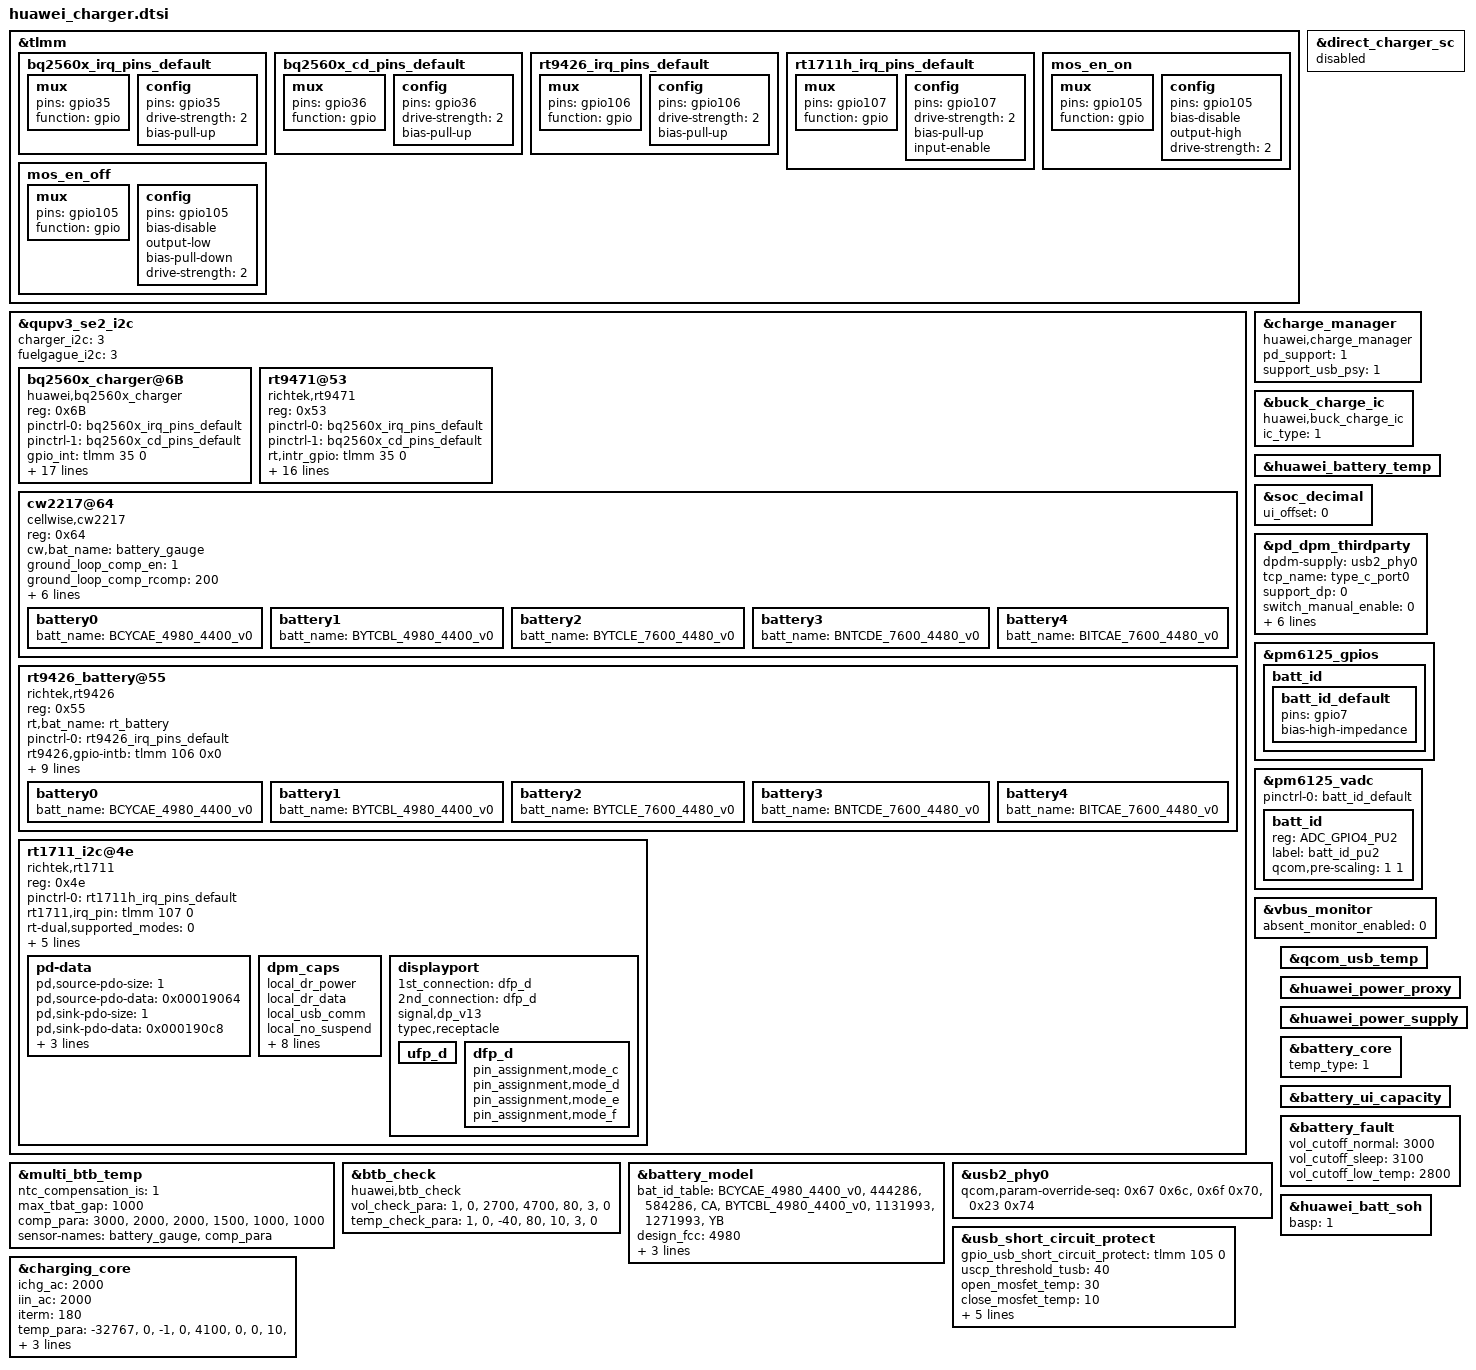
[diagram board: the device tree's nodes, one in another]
&tlmm {
	bq2560x_irq_pins_default: bq2560x_irq_pins_default {
		mux {
			pins = "gpio35";
			function = "gpio";
		};
		config {
			pins = "gpio35";
			drive-strength = <2>;
			bias-pull-up;
		};
	};

	bq2560x_cd_pins_default: bq2560x_cd_pins_default {
		mux {
			pins = "gpio36";
			function = "gpio";
		};
		config {
			pins = "gpio36";
			drive-strength = <2>;
			bias-pull-up;
		};
	};

	rt9426_irq_pins_default: rt9426_irq_pins_default {
		mux {
			pins = "gpio106";
			function = "gpio";
		};
		config {
			pins = "gpio106";
			drive-strength = <2>;
			bias-pull-up;
		};
	};

	rt1711h_irq_pins_default: rt1711h_irq_pins_default {
		mux {
			pins = "gpio107";
			function = "gpio";
		};
		config {
			pins = "gpio107";
			drive-strength = <2>;
			bias-pull-up;
			input-enable;
		};
	};

	mos_en_on: mos_en_on {
		mux {
			pins = "gpio105";
			function = "gpio";
		};

		config {
			pins = "gpio105";
			bias-disable;
			output-high;
			drive-strength = <2>; /* 2 MA */
		};
	};

	mos_en_off: mos_en_off {
		mux {
			pins = "gpio105";
			function = "gpio";
		};

		config {
			pins = "gpio105";
			bias-disable;
			output-low;
			bias-pull-down; /* PULL DOWN */
			drive-strength = <2>; /* 2 MA */
		};
	};
};

&direct_charger_sc {
	status = "disable";
};

&qupv3_se2_i2c {
	status = "ok";

	/* auto_key_info @ name: charger_i2c type: uint32 default: 0 */
	charger_i2c = <3>;
	/* auto_key_info @ name: fuelgague_i2c type: uint32 default: 0 */
	fuelgague_i2c = <3>;

	bq2560x_charger@6B{
		compatible = "huawei,bq2560x_charger";
		reg = <0x6B>;
		pinctrl-names = "bq2560x_irq_pins_default",
						"bq2560x_cd_pins_default";
		pinctrl-0 = <&bq2560x_irq_pins_default>;
		pinctrl-1 = <&bq2560x_cd_pins_default>;
		gpio_int = <&tlmm 35 0>;
		gpio_cd = <&tlmm 36 0>;
		bat_comp = <80>;
		vclamp = <224>;
		rilim = <124>;
		adc_channel_iin = <5>;
		adc_channel_vbat_sys = <14>;
		fcp_support = <0>;
		hiz_iin_limit = <1>;
		custom_cv = <4464>;
		chg_en_vac_ovp = <1>; /* vac_ovp:6.5v */
		dischg_vac_ovp = <1>; /* vac_ovp:6.5v */
		iprechg_cur = <120>; /* mA */
		otg_boost_vol = <2>; /* boost voltage:5.15v */
		ieoc = <180>; /* mA */
		charge-detect-enable;
		enable_redo_bc12;
		no_need_change_iterm;
		status = "ok";
	};

	rt9471@53 {
		compatible = "richtek,rt9471";
		reg = <0x53>;
		pinctrl-names = "bq2560x_irq_pins_default",
						"bq2560x_cd_pins_default";
		pinctrl-0 = <&bq2560x_irq_pins_default>;
		pinctrl-1 = <&bq2560x_cd_pins_default>;
		rt,intr_gpio = <&tlmm 35 0>;
		rt,ceb_gpio = <&tlmm 36 0>;
		charger_name = "rt9471";
		interrupt-names = "wdt", "vac_ov", "otg_fault";
		ichg = <1000>; /* mA */
		aicr = <500>; /* mA */
		acov = <6500>; /* mV */
		mivr = <4500>; /* mV */
		cv = <4400>; /* mV */
		custom_cv = <4464>;
		ieoc = <150>; /* mA */
		safe-tmr = <20>; /* hour */
		wdt = <40>; /* sec */
		mivr-track = <0>;
		en-te;
		/* en-jeita; */
		/* ceb-invert; */
		/* dis-i2c-tout; */
		en-qon-rst;
		/* auto-aicr; */
		charge-detect-enable;
		enable_redo_bc12;
		status = "ok";
	};

	cw2217@64 {
		compatible = "cellwise,cw2217";
		reg = <0x64>;
		cw,bat_name = "battery_gauge";
		status = "ok";
		ground_loop_comp_en = <1>;
		ground_loop_comp_rcomp = <200>;
		en_soft_reset = <1>;
		vbat_soc_table =
			"3783", "3781", "30",
			"3800", "3797", "36",
			"3825", "3821", "43",
			"3854", "3847", "49",
			"3892", "3882", "55",
			"3952", "3947", "62",
			"4004", "3996", "68",
			"4065", "4064", "74",
			"4136", "4132", "81",
			"4198", "4196", "87",
			"4274", "4274", "94",
			"4355", "4356", "100";
		battery0{
			batt_name = "BCYCAE_4980_4400_v0";
			#include "../../../huawei_charger/cw2217_BCYCAE_4980mAh_4V4_BT062.dtsi"
		};
		battery1{
			batt_name = "BYTCBL_4980_4400_v0";
			#include "../../../huawei_charger/cw2217_BYTCBL_4980mAh_4V4_BT062.dtsi"
		};
		battery2{
			batt_name = "BYTCLE_7600_4480_v0";
			#include "../../../huawei_charger/cw2217_BYTCLE_7600mAh_4V48_BT274.dtsi"
		};
		battery3{
			batt_name = "BNTCDE_7600_4480_v0";
			#include "../../../huawei_charger/cw2217_BNTCDE_7600mAh_4V48_BT274.dtsi"
		};
		battery4{
			batt_name = "BITCAE_7600_4480_v0";
			#include "../../../huawei_charger/cw2217_BITCAE_7600mAh_4V48_BT274.dtsi"
		};
	};

	rt9426_battery@55{
		reg = <0x55>;
		rt,bat_name = "rt_battery";
		compatible = "richtek,rt9426";
		pinctrl-names = "default";
		pinctrl-0 = <&rt9426_irq_pins_default>;
		rt9426,gpio-intb = <&tlmm 106 0x0>;
		need_reset_version = <9>;
		rt_config_ver = <14>; /* NOTICE: need increase 1 ,when update batter model param */
		ntc_compensation_is = <1>;
		ground_loop_comp_en = <1>;
		ground_loop_comp_rcomp = <200>;
		thirdparty_ffc_buck_para_flag = <1>;
		ntc_temp_compensation_para =
			"11000", "110",
			"10000", "100",
			"9000", "80",
			"8000", "60",
			"7000", "50",
			"6000", "40",
			"5000", "30",
			"3000", "20",
			"2000", "10";
		status = "ok";
		battery0{
			batt_name = "BCYCAE_4980_4400_v0";
			#include "../../../huawei_charger/rt9426_BCYCAE_4980mAh_4V4_BT062.dtsi"
		};
		battery1{
			batt_name = "BYTCBL_4980_4400_v0";
			#include "../../../huawei_charger/rt9426_BYTCBL_4980mAh_4V4_BT062.dtsi"
		};
		battery2{
			batt_name = "BYTCLE_7600_4480_v0";
			#include "../../../huawei_charger/rt9426_BYTCLE_7600mAh_4V48_BT274.dtsi"
		};
		battery3{
			batt_name = "BNTCDE_7600_4480_v0";
			#include "../../../huawei_charger/rt9426_BNTCDE_7600mAh_4V48_BT274.dtsi"
		};
		battery4{
			batt_name = "BITCAE_7600_4480_v0";
			#include "../../../huawei_charger/rt9426_BITCAE_7600mAh_4V48_BT274.dtsi"
		};
	};

	rt1711_i2c@4e {
		compatible = "richtek,rt1711";
		reg = <0x4e>;
		status = "ok";
		pinctrl-names = "default";
		pinctrl-0 = <&rt1711h_irq_pins_default>;
		rt1711,irq_pin = <&tlmm 107 0>;
		rt-dual,supported_modes = <0>; /* 0: dfp/ufp, 1: dfp, 2: ufp */
		rt-tcpc,name = "type_c_port0"; /* tcpc_device's name */
		rt-tcpc,role_def = <4>; /* 0: SNK Only, 1: SRC Only, 2: DRP, 3: Try.SRC, 4: Try.SNK */
		rt-tcpc,rp_level = <0>; /* 0: Default, 1: 1.5, 2: 3.0 */
		rt-tcpc,en_temporary_lock = <1>; /* add for qcom6225, attach_wake_lock */
		rt-tcpc,notifier_supply_num = <0>; /* the number of notifier supply */
		pd-data {
			pd,source-pdo-size = <1>;
			pd,source-pdo-data = <0x00019064>;  /*<0x019014>;*/

			pd,sink-pdo-size = <1>;
			pd,sink-pdo-data = <0x000190c8>;   /* 5V, 2A */

			/*
			No DP
			pd,id-vdo-size = <3>;
			pd,id-vdo-data = <0x500029cf 0x0 0x00010000>;
			With DP
			pd,id-vdo-size = <4>;
			pd,id-vdo-data = <0xec0029cf 0x0 0x00010000 0x11000001>;
			*/

			pd,id-vdo-size = <4>;
			pd,id-vdo-data = <0xec0012d1 0x0 0x107e0000 0x11000001>;
		};
		dpm_caps {
			local_dr_power;
			local_dr_data;
			// local_ext_power;
			local_usb_comm;
			// local_usb_suspend;
			// local_high_cap;
			// local_give_back;
			local_no_suspend;
			local_vconn_supply;

			attemp_enter_dp_mode;
			attemp_discover_cable;
			attemp_discover_id;

			/* 0: disable, 1: prefer_snk, 2: prefer_src */
			pr_check = <0>;
			// pr_reject_as_source;
			// pr_reject_as_sink;
			pr_check_gp_source;
			// pr_check_gp_sink;

			/* 0: disable, 1: prefer_ufp, 2: prefer_dfp */
			dr_check = <0>;
			// dr_reject_as_dfp;
			// dr_reject_as_ufp;

			snk_prefer_low_voltage;
			// snk_ignore_mismatch_current;
		};
		displayport {
			/* connection type = "both", "ufp_d", "dfp_d" */
			1st_connection = "dfp_d";
			2nd_connection = "dfp_d";
			signal,dp_v13;
			//signal,dp_gen2;
			//usbr20_not_used;
			typec,receptacle;
			ufp_d {
				//pin_assignment,mode_a;
				//pin_assignment,mode_b;
				//pin_assignment,mode_c;
				//pin_assignment,mode_d;
				//pin_assignment,mode_e;
			};
			dfp_d {
				/* Only support mode C & D */
				//pin_assignment,mode_a;
				//pin_assignment,mode_b;
				pin_assignment,mode_c;
				pin_assignment,mode_d;
				pin_assignment,mode_e;
				pin_assignment,mode_f;
			};
		};
	};
};

&charge_manager {
	compatible = "huawei,charge_manager";
	pd_support = <1>;
	support_usb_psy = <1>;
	status = "ok";
};

&buck_charge_ic {
	compatible = "huawei,buck_charge_ic";
	ic_type = <1>;
	status = "ok";
};

&huawei_battery_temp {
	status = "ok";
};

&multi_btb_temp {
	status = "ok";
	ntc_compensation_is = <1>;
	max_tbat_gap = <1000>;
	comp_para =
		"3000", "2000",
		"2000", "1500",
		"1000", "1000";
	sensor-names =
		"battery_gauge", "comp_para";
};

&soc_decimal {
	ui_offset = <0>;
	status = "ok";
};

&pd_dpm_thirdparty {
	dpdm-supply = <&usb2_phy0>;
	tcp_name = "type_c_port0";
	support_dp = <0>;
	switch_manual_enable = <0>;
	abnormal_cc_detection = <1>;
	cc_dynamic_protect = <2>;
	moisture_detection_by_cc_enable = <1>;
	cc_moisture_status_report = <1>;
	cc_abnormal_dmd_report_enable = <1>;
	emark_detect_enable = <0>;
	status = "ok";
};

&btb_check {
	compatible = "huawei,btb_check";
	vol_check_para = "1", "0", "2700", "4700", "80", "3", "0";
	temp_check_para = "1", "0", "-40", "80", "10", "3", "0";
	status = "ok";
};

&pm6125_gpios {
	batt_id {
		batt_id_default: batt_id_default {
			pins = "gpio7";
			bias-high-impedance;
		};
	};
};

&pm6125_vadc {
	pinctrl-0 = <&batt_id_default>;

	batt_id {
		reg = <ADC_GPIO4_PU2>;
		label = "batt_id_pu2";
		qcom,pre-scaling = <1 1>;
	};
};

&battery_model {
	bat_id_table =
		"BCYCAE_4980_4400_v0", "444286", "584286", "CA",
		"BYTCBL_4980_4400_v0", "1131993", "1271993", "YB";
	design_fcc = <4980>;
	support_iio = <1>;
	io-channels = <&pm6125_vadc ADC_GPIO4_PU2>;
	io-channel-names = "batt-id";
	id_adc_channel = <0>; /* useless but necessary for Qcom, set 0 as default */
	status = "ok";
};

&vbus_monitor {
	status = "ok";
	absent_monitor_enabled = <0>;
};

&usb2_phy0{
	qcom,param-override-seq = <0x67 0x6c>, //override_x0
				  <0x6f 0x70>, //override_x1
				  <0x23 0x74>; //override_x2
};

&qcom_usb_temp {
	status = "ok";
};

&usb_short_circuit_protect {
	gpio_usb_short_circuit_protect = <&tlmm 105 0>;
	uscp_threshold_tusb = <40>;
	open_mosfet_temp = <30>;
	close_mosfet_temp = <10>;
	open_hiz_temp = <30>;
	interval_switch_temp = <15>;
	use_pinctrl; /* for qcom6225, gpio use pinctrl */
	pinctrl-names = "mos_en_on", "mos_en_off";
	pinctrl-0 = <&mos_en_on>;
	pinctrl-1 = <&mos_en_off>;
	status = "ok";
};

&huawei_power_proxy {
	status = "ok";
};

&huawei_power_supply {
	 status = "ok";
};

&battery_core {
	temp_type = <1>;
	status = "ok";
};

&battery_ui_capacity {
	status = "ok";
};

&battery_fault {
	vol_cutoff_normal = <3000>;
	vol_cutoff_sleep = <3100>;
	vol_cutoff_low_temp = <2800>;
	status = "ok";
};

&huawei_batt_soh {
	basp = <1>;
	status = "ok";
};

&charging_core {
		status = "ok";
		ichg_ac = <2000>;
		iin_ac = <2000>;
		iterm = <180>;
		temp_para =
			"-32767","0","-1","0","4100","0",
			"0","10","-1","498","4400","0",
			"10","20","-1","1494","4400","3",
			"20","45","-1","-1","4400","3",
			"45","50","-1","1540","4100","3",
			"50","32767","-1","0","4100","0";

};
